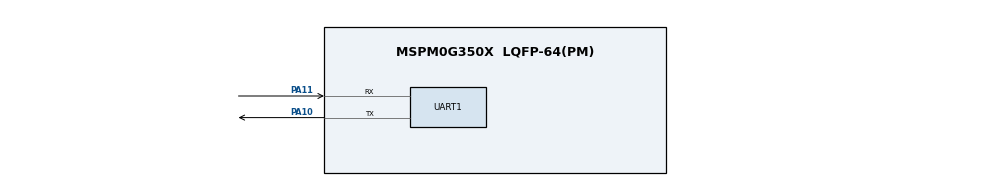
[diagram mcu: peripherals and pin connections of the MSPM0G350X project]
/**
 * @cliArgs --device "MSPM0G350X" --part "Default" --package "LQFP-64(PM)" --product "mspm0_sdk@2.06.00.05"
 * @versions {"tool":"1.21.0+3721"}
 */

/**
 * Import the modules used in this configuration.
 */
const GPIO   = scripting.addModule("/ti/driverlib/GPIO", {}, false);
const GPIO1  = GPIO.addInstance();
const SYSCTL = scripting.addModule("/ti/driverlib/SYSCTL");
const UART   = scripting.addModule("/ti/driverlib/UART", {}, false);
const UART1  = UART.addInstance();

/**
 * Write custom configuration values to the imported modules.
 */
GPIO1.$name                          = "GPIO_OLED_13";
GPIO1.associatedPins.create(2);
GPIO1.associatedPins[0].$name        = "GPIO_SCK";
GPIO1.associatedPins[0].initialValue = "SET";
GPIO1.associatedPins[0].assignedPort = "PORTA";
GPIO1.associatedPins[0].assignedPin  = "31";
GPIO1.associatedPins[1].initialValue = "SET";
GPIO1.associatedPins[1].assignedPort = "PORTA";
GPIO1.associatedPins[1].assignedPin  = "28";
GPIO1.associatedPins[1].$name        = "GPIO_SDA";

const Board = scripting.addModule("/ti/driverlib/Board", {}, false);

SYSCTL.forceDefaultClkConfig = true;

UART1.$name                    = "UART_0";
UART1.enabledInterrupts        = ["RX"];
UART1.targetBaudRate           = 115200;
UART1.peripheral.$assign       = "UART0";
UART1.peripheral.rxPin.$assign = "PA11";
UART1.peripheral.txPin.$assign = "PA10";
UART1.txPinConfig.$name        = "ti_driverlib_gpio_GPIOPinGeneric0";
UART1.rxPinConfig.$name        = "ti_driverlib_gpio_GPIOPinGeneric1";

/**
 * Pinmux solution for unlocked pins/peripherals. This ensures that minor changes to the automatic solver in a future
 * version of the tool will not impact the pinmux you originally saw.  These lines can be completely deleted in order to
 * re-solve from scratch.
 */
GPIO1.associatedPins[0].pin.$suggestSolution = "PA31";
GPIO1.associatedPins[1].pin.$suggestSolution = "PA28";
Board.peripheral.$suggestSolution            = "DEBUGSS";
Board.peripheral.swclkPin.$suggestSolution   = "PA20";
Board.peripheral.swdioPin.$suggestSolution   = "PA19";
SYSCTL.peripheral.$suggestSolution           = "SYSCTL";
